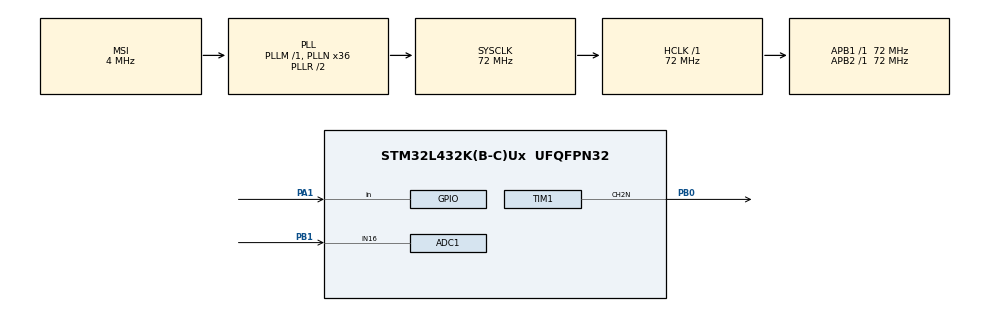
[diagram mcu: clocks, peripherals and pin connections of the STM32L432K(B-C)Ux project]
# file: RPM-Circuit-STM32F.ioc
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ADC1.Channel-2\#ChannelRegularConversion=ADC_CHANNEL_16
ADC1.ContinuousConvMode=ENABLE
ADC1.DMAContinuousRequests=ENABLE
ADC1.NbrOfConversionFlag=1
ADC1.OffsetNumber-2\#ChannelRegularConversion=ADC_OFFSET_NONE
ADC1.Rank-2\#ChannelRegularConversion=1
ADC1.SamplingTime-2\#ChannelRegularConversion=ADC_SAMPLETIME_2CYCLES_5
ADC1.master=1
Dma.ADC1.0.Direction=DMA_PERIPH_TO_MEMORY
Dma.ADC1.0.Instance=DMA1_Channel1
Dma.ADC1.0.MemDataAlignment=DMA_MDATAALIGN_HALFWORD
Dma.ADC1.0.MemInc=DMA_MINC_ENABLE
Dma.ADC1.0.Mode=DMA_CIRCULAR
Dma.ADC1.0.PeriphDataAlignment=DMA_PDATAALIGN_HALFWORD
Dma.ADC1.0.PeriphInc=DMA_PINC_DISABLE
Dma.ADC1.0.Priority=DMA_PRIORITY_LOW
Dma.Request0=ADC1
Mcu.Family=STM32L4
Mcu.Name=STM32L432K(B-C)Ux
Mcu.Package=UFQFPN32
NVIC.DMA1_Channel1_IRQn=true\:0\:0\:false\:false\:true\:false\:true\:true
NVIC.PriorityGroup=NVIC_PRIORITYGROUP_4
PA1.Signal=GPIO_Input
PB0.Mode=PWM Generation2 CH2N
PB0.Signal=TIM1_CH2N
PB1.Signal=ADCx_IN16
ProjectManager.HeapSize=0x200
ProjectManager.StackSize=0x400
ProjectManager.TargetToolchain=CMake
RCC.ADCCLockSelection=RCC_ADCCLKSOURCE_SYSCLK
RCC.ADCFreq_Value=72000000
RCC.AHBFreq_Value=72000000
RCC.APB1Freq_Value=72000000
RCC.APB1TimFreq_Value=72000000
RCC.APB2Freq_Value=72000000
RCC.APB2TimFreq_Value=72000000
RCC.CortexFreq_Value=72000000
RCC.HCLKFreq_Value=72000000
RCC.HSE_VALUE=8000000
RCC.HSI48_VALUE=48000000
RCC.HSI_VALUE=16000000
RCC.LSE_VALUE=32768
RCC.MSI_VALUE=4000000
RCC.PLLN=36
RCC.PLLSAI1N=16
RCC.SYSCLKFreq_VALUE=72000000
RCC.SYSCLKSource=RCC_SYSCLKSOURCE_PLLCLK
RCC.USBFreq_Value=32000000
RCC.VCOOutputFreq_Value=144000000
SH.ADCx_IN16.0=ADC1_IN16,IN16-Single-Ended
TIM1.AutoReloadPreload=TIM_AUTORELOAD_PRELOAD_ENABLE
TIM1.Channel-PWM\ Generation2\ CH2N=TIM_CHANNEL_2
TIM16.AutoReloadPreload=TIM_AUTORELOAD_PRELOAD_ENABLE
VP_TIM16_VS_ClockSourceINT.Mode=Enable_Timer
board=custom

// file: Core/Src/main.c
/* USER CODE BEGIN Header */
/**
  ******************************************************************************
  * @file           : main.c
  * @brief          : Main program body
  ******************************************************************************
  * @attention
  *
  * Copyright (c) 2026 STMicroelectronics.
  * All rights reserved.
  *
  * This software is licensed under terms that can be found in the LICENSE file
  * in the root directory of this software component.
  * If no LICENSE file comes with this software, it is provided AS-IS.
  *
  ******************************************************************************
  */
/* USER CODE END Header */
#include "main.h"

/* USER CODE BEGIN Includes */
#include <stdint.h>
#define TICKS_PER_HOUR 3600000.0f
#define TICKS_PER_MINUTE 60000.0f
#define TICKS_PER_SECOND 1000.0f
#define DIAMETER_OF_WHEEL_IN_M 0.1f
#define CIRCUMFERENCE_OF_WHEEL_IN_M 3.14159f * DIAMETER_OF_WHEEL_IN_M
#define CIRCUMERENCE_OF_WHEEL_IN_MILES CIRCUMFERENCE_OF_WHEEL_IN_M / 1609.34f

#define SECONDS_PER_HOUR 3600.0f
/* USER CODE END Includes */

ADC_HandleTypeDef hadc1;
DMA_HandleTypeDef hdma_adc1;

TIM_HandleTypeDef htim1;
TIM_HandleTypeDef htim16;

/* USER CODE BEGIN PV */
volatile uint32_t currentPulseTime = 0;
volatile uint32_t prevPulseTime = 0;
volatile uint16_t AD_RES = 0;
uint32_t AD_RES_BUFFER[1];

float ticksBetweenPulses = 0;
float frequency = 0;
float metersPerSecond = 0;
float milesPerHour = 0;
/* USER CODE END PV */

void SystemClock_Config(void);
static void MX_GPIO_Init(void);
static void MX_DMA_Init(void);
static void MX_ADC1_Init(void);
static void MX_TIM1_Init(void);
static void MX_TIM16_Init(void);

int main(void)
{

  /* MCU Configuration--------------------------------------------------------*/

  /* Reset of all peripherals, Initializes the Flash interface and the Systick. */
  HAL_Init();

  /* Configure the system clock */
  SystemClock_Config();

  /* Initialize all configured peripherals */
  MX_GPIO_Init();
  MX_DMA_Init();
  MX_ADC1_Init();
  MX_TIM1_Init();
  MX_TIM16_Init();
  /* USER CODE BEGIN 2 */
  volatile GPIO_PinState pinState = HAL_GPIO_ReadPin(GPIOA, GPIO_PIN_1);
  HAL_ADC_Start(&hadc1);
  HAL_ADC_Start_DMA(&hadc1, AD_RES_BUFFER, 1);

  /* USER CODE END 2 */

  /* Infinite loop */
  /* USER CODE BEGIN WHILE */
  while (1)
  {

    // PWM Generation
    AD_RES = AD_RES_BUFFER[0];
    TIM1->CCR2 = AD_RES << 4; // Set the PWM duty cycle based on the ADC value

    if(HAL_GPIO_ReadPin(GPIOA, GPIO_PIN_1) == GPIO_PIN_SET)
    {
      //A1 high
      pinState = GPIO_PIN_SET;

    }
    else if(HAL_GPIO_ReadPin(GPIOA, GPIO_PIN_1) == GPIO_PIN_RESET)
    {
      //A1 low

        if(pinState != GPIO_PIN_RESET)
      {
        currentPulseTime = HAL_GetTick();
        ticksBetweenPulses = currentPulseTime - prevPulseTime;
        frequency = TICKS_PER_SECOND / ticksBetweenPulses;
        metersPerSecond = frequency * CIRCUMFERENCE_OF_WHEEL_IN_M;
        milesPerHour = frequency * SECONDS_PER_HOUR * CIRCUMERENCE_OF_WHEEL_IN_MILES;

        prevPulseTime = currentPulseTime;

      }
       pinState = GPIO_PIN_RESET;

    }

  }
    /* USER CODE END WHILE */

}

void SystemClock_Config(void)
{
  RCC_OscInitTypeDef RCC_OscInitStruct = {0};
  RCC_ClkInitTypeDef RCC_ClkInitStruct = {0};

  /** Configure the main internal regulator output voltage
  */
  if (HAL_PWREx_ControlVoltageScaling(PWR_REGULATOR_VOLTAGE_SCALE1) != HAL_OK)
  {
    Error_Handler();
  }

  /** Initializes the RCC Oscillators according to the specified parameters
  * in the RCC_OscInitTypeDef structure.
  */
  RCC_OscInitStruct.OscillatorType = RCC_OSCILLATORTYPE_MSI;
  RCC_OscInitStruct.MSIState = RCC_MSI_ON;
  RCC_OscInitStruct.MSICalibrationValue = 0;
  RCC_OscInitStruct.MSIClockRange = RCC_MSIRANGE_6;
  RCC_OscInitStruct.PLL.PLLState = RCC_PLL_ON;
  RCC_OscInitStruct.PLL.PLLSource = RCC_PLLSOURCE_MSI;
  RCC_OscInitStruct.PLL.PLLM = 1;
  RCC_OscInitStruct.PLL.PLLN = 36;
  RCC_OscInitStruct.PLL.PLLP = RCC_PLLP_DIV7;
  RCC_OscInitStruct.PLL.PLLQ = RCC_PLLQ_DIV2;
  RCC_OscInitStruct.PLL.PLLR = RCC_PLLR_DIV2;
  if (HAL_RCC_OscConfig(&RCC_OscInitStruct) != HAL_OK)
  {
    Error_Handler();
  }

  /** Initializes the CPU, AHB and APB buses clocks
  */
  RCC_ClkInitStruct.ClockType = RCC_CLOCKTYPE_HCLK|RCC_CLOCKTYPE_SYSCLK
                              |RCC_CLOCKTYPE_PCLK1|RCC_CLOCKTYPE_PCLK2;
  RCC_ClkInitStruct.SYSCLKSource = RCC_SYSCLKSOURCE_PLLCLK;
  RCC_ClkInitStruct.AHBCLKDivider = RCC_SYSCLK_DIV1;
  RCC_ClkInitStruct.APB1CLKDivider = RCC_HCLK_DIV1;
  RCC_ClkInitStruct.APB2CLKDivider = RCC_HCLK_DIV1;

  if (HAL_RCC_ClockConfig(&RCC_ClkInitStruct, FLASH_LATENCY_4) != HAL_OK)
  {
    Error_Handler();
  }
}

static void MX_ADC1_Init(void)
{

  ADC_ChannelConfTypeDef sConfig = {0};

  /** Common config
  */
  hadc1.Instance = ADC1;
  hadc1.Init.ClockPrescaler = ADC_CLOCK_ASYNC_DIV1;
  hadc1.Init.Resolution = ADC_RESOLUTION_12B;
  hadc1.Init.DataAlign = ADC_DATAALIGN_RIGHT;
  hadc1.Init.ScanConvMode = ADC_SCAN_DISABLE;
  hadc1.Init.EOCSelection = ADC_EOC_SINGLE_CONV;
  hadc1.Init.LowPowerAutoWait = DISABLE;
  hadc1.Init.ContinuousConvMode = ENABLE;
  hadc1.Init.NbrOfConversion = 1;
  hadc1.Init.DiscontinuousConvMode = DISABLE;
  hadc1.Init.ExternalTrigConv = ADC_SOFTWARE_START;
  hadc1.Init.ExternalTrigConvEdge = ADC_EXTERNALTRIGCONVEDGE_NONE;
  hadc1.Init.DMAContinuousRequests = ENABLE;
  hadc1.Init.Overrun = ADC_OVR_DATA_PRESERVED;
  hadc1.Init.OversamplingMode = DISABLE;
  if (HAL_ADC_Init(&hadc1) != HAL_OK)
  {
    Error_Handler();
  }

  /** Configure Regular Channel
  */
  sConfig.Channel = ADC_CHANNEL_16;
  sConfig.Rank = ADC_REGULAR_RANK_1;
  sConfig.SamplingTime = ADC_SAMPLETIME_2CYCLES_5;
  sConfig.SingleDiff = ADC_SINGLE_ENDED;
  sConfig.OffsetNumber = ADC_OFFSET_NONE;
  sConfig.Offset = 0;
  if (HAL_ADC_ConfigChannel(&hadc1, &sConfig) != HAL_OK)
  {
    Error_Handler();
  }

}

static void MX_TIM1_Init(void)
{

  TIM_MasterConfigTypeDef sMasterConfig = {0};
  TIM_OC_InitTypeDef sConfigOC = {0};
  TIM_BreakDeadTimeConfigTypeDef sBreakDeadTimeConfig = {0};

  htim1.Instance = TIM1;
  htim1.Init.Prescaler = 0;
  htim1.Init.CounterMode = TIM_COUNTERMODE_UP;
  htim1.Init.Period = 65535;
  htim1.Init.ClockDivision = TIM_CLOCKDIVISION_DIV1;
  htim1.Init.RepetitionCounter = 0;
  htim1.Init.AutoReloadPreload = TIM_AUTORELOAD_PRELOAD_ENABLE;
  if (HAL_TIM_PWM_Init(&htim1) != HAL_OK)
  {
    Error_Handler();
  }
  sMasterConfig.MasterOutputTrigger = TIM_TRGO_RESET;
  sMasterConfig.MasterOutputTrigger2 = TIM_TRGO2_RESET;
  sMasterConfig.MasterSlaveMode = TIM_MASTERSLAVEMODE_DISABLE;
  if (HAL_TIMEx_MasterConfigSynchronization(&htim1, &sMasterConfig) != HAL_OK)
  {
    Error_Handler();
  }
  sConfigOC.OCMode = TIM_OCMODE_PWM1;
  sConfigOC.Pulse = 0;
  sConfigOC.OCPolarity = TIM_OCPOLARITY_HIGH;
  sConfigOC.OCNPolarity = TIM_OCNPOLARITY_HIGH;
  sConfigOC.OCFastMode = TIM_OCFAST_DISABLE;
  sConfigOC.OCIdleState = TIM_OCIDLESTATE_RESET;
  sConfigOC.OCNIdleState = TIM_OCNIDLESTATE_RESET;
  if (HAL_TIM_PWM_ConfigChannel(&htim1, &sConfigOC, TIM_CHANNEL_2) != HAL_OK)
  {
    Error_Handler();
  }
  sBreakDeadTimeConfig.OffStateRunMode = TIM_OSSR_DISABLE;
  sBreakDeadTimeConfig.OffStateIDLEMode = TIM_OSSI_DISABLE;
  sBreakDeadTimeConfig.LockLevel = TIM_LOCKLEVEL_OFF;
  sBreakDeadTimeConfig.DeadTime = 0;
  sBreakDeadTimeConfig.BreakState = TIM_BREAK_DISABLE;
  sBreakDeadTimeConfig.BreakPolarity = TIM_BREAKPOLARITY_HIGH;
  sBreakDeadTimeConfig.BreakFilter = 0;
  sBreakDeadTimeConfig.Break2State = TIM_BREAK2_DISABLE;
  sBreakDeadTimeConfig.Break2Polarity = TIM_BREAK2POLARITY_HIGH;
  sBreakDeadTimeConfig.Break2Filter = 0;
  sBreakDeadTimeConfig.AutomaticOutput = TIM_AUTOMATICOUTPUT_DISABLE;
  if (HAL_TIMEx_ConfigBreakDeadTime(&htim1, &sBreakDeadTimeConfig) != HAL_OK)
  {
    Error_Handler();
  }
  HAL_TIM_MspPostInit(&htim1);

}

static void MX_TIM16_Init(void)
{

  htim16.Instance = TIM16;
  htim16.Init.Prescaler = 0;
  htim16.Init.CounterMode = TIM_COUNTERMODE_UP;
  htim16.Init.Period = 65535;
  htim16.Init.ClockDivision = TIM_CLOCKDIVISION_DIV1;
  htim16.Init.RepetitionCounter = 0;
  htim16.Init.AutoReloadPreload = TIM_AUTORELOAD_PRELOAD_ENABLE;
  if (HAL_TIM_Base_Init(&htim16) != HAL_OK)
  {
    Error_Handler();
  }

}

static void MX_DMA_Init(void)
{

  /* DMA controller clock enable */
  __HAL_RCC_DMA1_CLK_ENABLE();

  /* DMA interrupt init */
  /* DMA1_Channel1_IRQn interrupt configuration */
  HAL_NVIC_SetPriority(DMA1_Channel1_IRQn, 0, 0);
  HAL_NVIC_EnableIRQ(DMA1_Channel1_IRQn);

}

static void MX_GPIO_Init(void)
{
  GPIO_InitTypeDef GPIO_InitStruct = {0};

  /* GPIO Ports Clock Enable */
  __HAL_RCC_GPIOA_CLK_ENABLE();
  __HAL_RCC_GPIOB_CLK_ENABLE();

  /*Configure GPIO pin : PA1 */
  GPIO_InitStruct.Pin = GPIO_PIN_1;
  GPIO_InitStruct.Mode = GPIO_MODE_INPUT;
  GPIO_InitStruct.Pull = GPIO_NOPULL;
  HAL_GPIO_Init(GPIOA, &GPIO_InitStruct);

}

void Error_Handler(void)
{
  __disable_irq();
  while (1)
  {
  }
}
